# DSS_CTRL register map
Vendor: Texas Instruments
Peripheral module from a debugger description file (folder awr2x44p).
Registers are 32-bit, read-write, no defined reset value unless marked. A register's access mark holds for its fields unless they carry their own. Offsets are as the file gives them; lines under a group give offsets from that group; [hi:lo] are bit positions; {n}, {i} and the like mark numbered series; 'fields as' and 'values as' point back to an identical list; <NAME> marks a mode.

## DSS_CTRL (part 1 of 2)
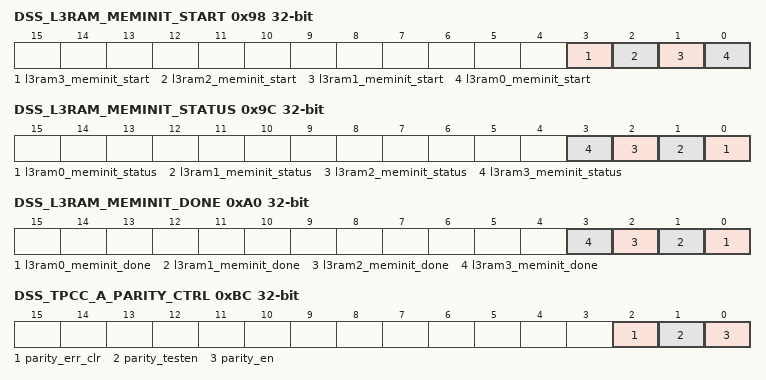
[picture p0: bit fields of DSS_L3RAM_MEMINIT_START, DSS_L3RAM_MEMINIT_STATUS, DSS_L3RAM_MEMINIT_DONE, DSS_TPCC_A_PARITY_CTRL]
0x98 DSS_L3RAM_MEMINIT_START
  [3] l3ram3_meminit_start — Write pulse bit field:Start Memory intialization of TPCC A Param memory. Write 0x1 to start memory initilization. Write 0x0 after ensuring Memory intilization is in progress or has completed. Before starting new initilzation sequence ensure that there is no initilization sequence is in progress (ie L3RAM_MEMINIT_STATUS should be 0x0) and clear any previouls complettion status(ie write 0x1 to clear L3RAM_MEMINIT_DONE)
  [2] l3ram2_meminit_start — Write pulse bit field: Start Memory intialization of TPCC A Param memory. Write 0x1 to start memory initilization. Write 0x0 after ensuring Memory intilization is in progress or has completed. Before starting new initilzation sequence ensure that there is no initilization sequence is in progress (ie L3RAM_MEMINIT_STATUS should be 0x0) and clear any previouls complettion status(ie write 0x1 to clear L3RAM_MEMINIT_DONE)
  [1] l3ram1_meminit_start — Write pulse bit field: Start Memory intialization of TPCC A Param memory. Write 0x1 to start memory initilization. Write 0x0 after ensuring Memory intilization is in progress or has completed. Before starting new initilzation sequence ensure that there is no initilization sequence is in progress (ie L3RAM_MEMINIT_STATUS should be 0x0) and clear any previouls complettion status(ie write 0x1 to clear L3RAM_MEMINIT_DONE)
  [0] l3ram0_meminit_start — Write pulse bit field: Start Memory intialization of TPCC A Param memory. Write 0x1 to start memory initilization. Write 0x0 after ensuring Memory intilization is in progress or has completed. Before starting new initilzation sequence ensure that there is no initilization sequence is in progress (ie L3RAM_MEMINIT_STATUS should be 0x0) and clear any previouls complettion status(ie write 0x1 to clear L3RAM_MEMINIT_DONE)
0x9C DSS_L3RAM_MEMINIT_STATUS ro
  [n] l3ram{n}_meminit_status (n=0..3) — Status field. Read value 0x1 indicates previously triggered Memory intialization of TPCC A Param memory is in progress.
0xA0 DSS_L3RAM_MEMINIT_DONE
  [n] l3ram{n}_meminit_done (n=0..3) — Rising Edge Capture reg (write 1 to clear): Status field. Read value 0x1 indicates previously triggered Memory intialization of TPCC A Param memory is complte. Write 0x1 to clear status. Refer TPCC Memory initialization sequnce in EDMA section for more details
0xB0 DSS_MAILBOX_MEMINIT_START
  [0] meminit_start — Write pulse bit field: Start Memory intialization of TPCC A Param memory. Write 0x1 to start memory initilization. Write 0x0 after ensuring Memory intilization is in progress or has completed. Before starting new initilzation sequence ensure that there is no initilization sequence is in progress (ie L3RAM_MEMINIT_STATUS should be 0x0) and clear any previouls complettion status(ie write 0x1 to clear L3RAM_MEMINIT_DONE)
0xB4 DSS_MAILBOX_MEMINIT_STATUS ro
  [0] meminit_status — Status field. Read value 0x1 indicates previously triggered Memory intialization of TPCC A Param memory is in progress.
0xB8 DSS_MAILBOX_MEMINIT_DONE
  [0] meminit_done — Rising Edge Capture reg (write 1 to clear): Status field. Read value 0x1 indicates previously triggered Memory intialization of TPCC A Param memory is complte. Write 0x1 to clear status. Refer TPCC Memory initialization sequnce in EDMA section for more details
0xBC DSS_TPCC_A_PARITY_CTRL
  [2] parity_err_clr — Write pulse bit field: Write 0x1 to clear the Parit Error status for TPCC
  [1] parity_testen — Enable Parity Test for TPCC. Write 0x1 : Parity Test is enabled on PARAM memory
  [0] parity_en — Enable Parity for TPCC. Write 0x1 : Parity is enabled on PARAM memory
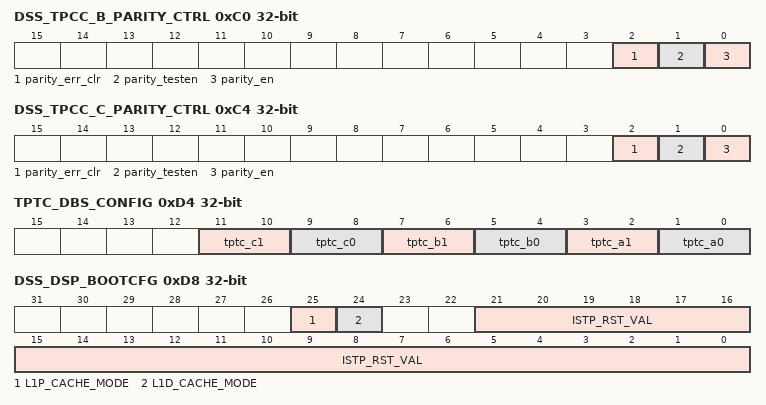
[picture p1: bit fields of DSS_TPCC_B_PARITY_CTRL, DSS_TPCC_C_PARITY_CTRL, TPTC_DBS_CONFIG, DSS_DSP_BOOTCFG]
0xC0 DSS_TPCC_B_PARITY_CTRL
  fields as DSS_TPCC_A_PARITY_CTRL
0xC4 DSS_TPCC_C_PARITY_CTRL
  fields as DSS_TPCC_A_PARITY_CTRL
0xC8 DSS_TPCC_A_PARITY_STATUS ro
  [7:0] parity_addr — TPCC Error Address at which Parity Error occurred
0xCC DSS_TPCC_B_PARITY_STATUS ro
  fields as DSS_TPCC_A_PARITY_STATUS
0xD0 DSS_TPCC_C_PARITY_STATUS ro
  [8:0] parity_addr — TPCC Error Address at which Parity Error occurred
0xD4 TPTC_DBS_CONFIG
  [11:10] tptc_c1 — Max Burst size tieoff value for TPTC C1
  [9:8] tptc_c0 — Max Burst size tieoff value for TPTC C0
  [7:6] tptc_b1 — Max Burst size tieoff value for TPTC B0
  [5:4] tptc_b0 — Max Burst size tieoff value for TPTC B0
  [3:2] tptc_a1 — Max Burst size tieoff value for TPTC A1
  [1:0] tptc_a0 — Max Burst size tieoff value for TPTC A0
0xD8 DSS_DSP_BOOTCFG
  [25] L1P_CACHE_MODE — DSP Boot Configuration : L1P Cache Mode
  [24] L1D_CACHE_MODE — DSP Boot Configuration : L1D Cache Mode
  [21:0] ISTP_RST_VAL — DSP Boot Configuration : Reset Vector
0xDC DSS_DSP_NMI_GATE
  [2:0] gate — Write 3b111 to gate the Non Maskable Interrupt to the DSP. This is not expected to be used
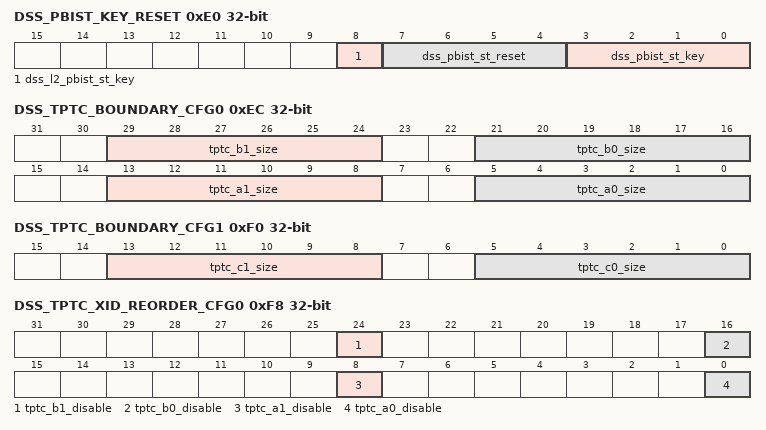
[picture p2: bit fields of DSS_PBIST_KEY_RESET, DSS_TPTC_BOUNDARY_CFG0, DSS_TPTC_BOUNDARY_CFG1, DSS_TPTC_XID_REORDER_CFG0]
0xE0 DSS_PBIST_KEY_RESET
  [8] dss_l2_pbist_st_key — DSS L2 PBIST Selftest Key.
  [7:4] dss_pbist_st_reset — DSS PBIST controller will be brought out of reset when value is 0xA
  [3:0] dss_pbist_st_key — DSS PBIST Selftest Key. Valid value is 0x5
0xE4 DSS_PBIST_REG0
  [31:0] dss_pbist_reg0 — DSP PBIST registers
0xE8 DSS_PBIST_REG1
  [31:0] dss_pbist_reg1 — DSP PBIST registers
0xEC DSS_TPTC_BOUNDARY_CFG0
  [29:24] tptc_b1_size — 6 bit signal used for deciding the boundary crossing size for CID-RID-SID reordering of TPTC Example: writing 6d19 decidies boundary to be 2^19 i.e. 512 KB
  [21:16] tptc_b0_size — 6 bit signal used for deciding the boundary crossing size for CID-RID-SID reordering of TPTC Example: writing 6d19 decidies boundary to be 2^19 i.e. 512 KB
  [13:8] tptc_a1_size — 6 bit signal used for deciding the boundary crossing size for CID-RID-SID reordering of TPTC Example: writing 6d19 decidies boundary to be 2^19 i.e. 512 KB
  [5:0] tptc_a0_size — 6 bit signal used for deciding the boundary crossing size for CID-RID-SID reordering of TPTC Example: writing 6d19 decidies boundary to be 2^19 i.e. 512 KB
0xF0 DSS_TPTC_BOUNDARY_CFG1
  [13:8] tptc_c1_size — 6 bit signal used for deciding the boundary crossing size for CID-RID-SID reordering of TPTC Example: writing 6d19 decidies boundary to be 2^19 i.e. 512 KB
  [5:0] tptc_c0_size — 6 bit signal used for deciding the boundary crossing size for CID-RID-SID reordering of TPTC Example: writing 6d19 decidies boundary to be 2^19 i.e. 512 KB
0xF8 DSS_TPTC_XID_REORDER_CFG0
  [24] tptc_b1_disable — Writing 1b1 will disable the CID-RID-SID reodering feature for the TPTC instance
  [16] tptc_b0_disable — Writing 1b1 will disable the CID-RID-SID reodering feature for the TPTC instance
  [8] tptc_a1_disable — Writing 1b1 will disable the CID-RID-SID reodering feature for the TPTC instance
  [0] tptc_a0_disable — Writing 1b1 will disable the CID-RID-SID reodering feature for the TPTC instance
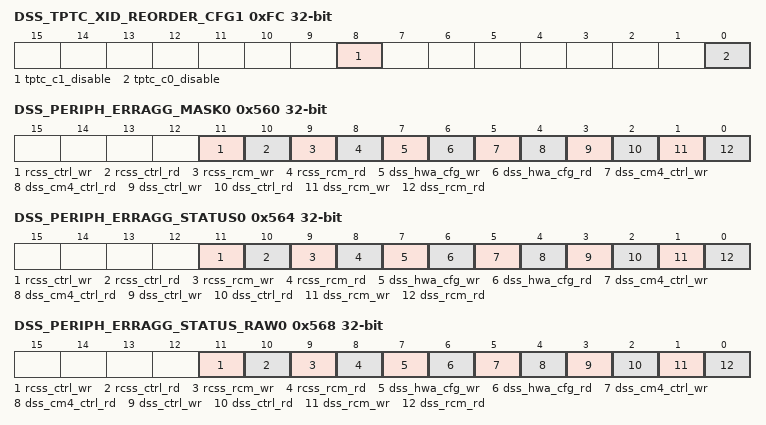
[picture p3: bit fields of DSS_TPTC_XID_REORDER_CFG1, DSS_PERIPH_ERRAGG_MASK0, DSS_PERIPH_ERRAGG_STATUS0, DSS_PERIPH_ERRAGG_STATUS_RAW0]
0xFC DSS_TPTC_XID_REORDER_CFG1
  [8] tptc_c1_disable — Writing 1b1 will disable the CID-RID-SID reodering feature for the TPTC instance
  [0] tptc_c0_disable — Writing 1b1 will disable the CID-RID-SID reodering feature for the TPTC instance
{0x108+4i} ESM_GATING{i} (i=0..3)
  [31:0] esm_gating — Bit3:0 : writing 000 will ungate the DSS ESM Group2 Error {8i} Bit7:4 : writing 000 will ungate the DSS ESM Group2 Error {8i+1} Bit31:28 : writing 000 will ungate the DSS ESM Group2 Error {8i+7}
0x560 DSS_PERIPH_ERRAGG_MASK0
  [11] rcss_ctrl_wr — Mask the Write error from RCSS_CTRL space from generating an error DSS_PERIPH_ERRAGG to the Processor
  [10] rcss_ctrl_rd — Mask the Read error from RCSS_CTRL space from generating an error DSS_PERIPH_ERRAGG to the Processor
  [9] rcss_rcm_wr — Mask the Write error from RCSS_RCM space from generating an error DSS_PERIPH_ERRAGG to the Processor
  [8] rcss_rcm_rd — Mask the Read error from RCSS_RCM space from generating an error DSS_PERIPH_ERRAGG to the Processor
  [7] dss_hwa_cfg_wr — Mask the Write error from DSS_HWA_CFG space from generating an error DSS_PERIPH_ERRAGG to the Processor
  [6] dss_hwa_cfg_rd — Mask the Read error from DSS_HWA_CFG space from generating an error DSS_PERIPH_ERRAGG to the Processor
  [5] dss_cm4_ctrl_wr — Mask the Write error from DSS_CM4_CTRL space from generating an error DSS_PERIPH_ERRAGG to the Processor
  [4] dss_cm4_ctrl_rd — Mask the Read error from DSS_CM4_CTRL space from generating an error DSS_PERIPH_ERRAGG to the Processor
  [3] dss_ctrl_wr — Mask the Write error from DSS_CTRL space from generating an error DSS_PERIPH_ERRAGG to the Processor
  [2] dss_ctrl_rd — Mask the Read error from DSS_CTRL space from generating an error DSS_PERIPH_ERRAGG to the Processor
  [1] dss_rcm_wr — Mask the Write error from DSS_RCM space from generating an error DSS_PERIPH_ERRAGG to the Processor
  [0] dss_rcm_rd — Mask the Read error from DSS_RCM space from generating an error DSS_PERIPH_ERRAGG to the Processor
0x564 DSS_PERIPH_ERRAGG_STATUS0
  [11] rcss_ctrl_wr — Rising Edge Capture reg (write 1 to clear): Status of the Write error from RCSS_CTRL space. Read 1 : Read error occurred on access to the RCSS_CTRL space
  [10] rcss_ctrl_rd — Rising Edge Capture reg (write 1 to clear): Status of the Read error from RCSS_CTRL space. Read 1 : Read error occurred on access to the RCSS_CTRL space
  [9] rcss_rcm_wr — Rising Edge Capture reg (write 1 to clear): Status of the Write error from RCSS_RCM space. Read 1 : Read error occurred on access to the RCSS_RCM space
  [8] rcss_rcm_rd — Rising Edge Capture reg (write 1 to clear): Status of the Read error from RCSS_RCM space. Read 1 : Read error occurred on access to the RCSS_RCM space
  [7] dss_hwa_cfg_wr — Rising Edge Capture reg (write 1 to clear): Status of the Write error from DSS_HWA_CFG space. Read 1 : Read error occurred on access to the DSS_HWA_CFG space
  [6] dss_hwa_cfg_rd — Rising Edge Capture reg (write 1 to clear): Status of the Read error from DSS_HWA_CFG space. Read 1 : Read error occurred on access to the DSS_HWA_CFG space
  [5] dss_cm4_ctrl_wr — Rising Edge Capture reg (write 1 to clear): Status of the Write error from DSS_CM4_CTRL space. Read 1 : Read error occurred on access to the DSS_CM4_CTRL space
  [4] dss_cm4_ctrl_rd — Rising Edge Capture reg (write 1 to clear): Status of the Read error from DSS_CM4_CTRL space. Read 1 : Read error occurred on access to the DSS_CM4_CTRL space
  [3] dss_ctrl_wr — Rising Edge Capture reg (write 1 to clear): Status of the Write error from DSS_CTRL space. Read 1 : Read error occurred on access to the DSS_CTRL space
  [2] dss_ctrl_rd — Rising Edge Capture reg (write 1 to clear): Status of the Read error from DSS_CTRL space. Read 1 : Read error occurred on access to the DSS_CTRL space
  [1] dss_rcm_wr — Rising Edge Capture reg (write 1 to clear): Status of the Write error from DSS_RCM space. Read 1 : Read error occurred on access to the DSS_RCM space
  [0] dss_rcm_rd — Rising Edge Capture reg (write 1 to clear): Rising Edge Capture reg (write 1 to clear): Status of the Read error from DSS_RCM space. Read 1 : Read error occurred on access to the DSS_RCM space
0x568 DSS_PERIPH_ERRAGG_STATUS_RAW0
  [11] rcss_ctrl_wr — Rising Edge Capture reg (write 1 to clear): Raw Status of the Write error from RCSS_CTRL space irrespective of it being masked. Read 1 : Read error occurred on access to the RCSS_CTRL space
  [10] rcss_ctrl_rd — Rising Edge Capture reg (write 1 to clear): Raw Status of the Read error from RCSS_CTRL space irrespective of it being masked. Read 1 : Read error occurred on access to the RCSS_CTRL space
  [9] rcss_rcm_wr — Rising Edge Capture reg (write 1 to clear): Raw Status of the Write error from RCSS_RCM space irrespective of it being masked. Read 1 : Read error occurred on access to the RCSS_RCM space
  [8] rcss_rcm_rd — Rising Edge Capture reg (write 1 to clear): Raw Status of the Read error from RCSS_RCM space irrespective of it being masked. Read 1 : Read error occurred on access to the RCSS_RCM space
  [7] dss_hwa_cfg_wr — Rising Edge Capture reg (write 1 to clear): Raw Status of the Write error from DSS_HWA_CFG space irrespective of it being masked. Read 1 : Read error occurred on access to the DSS_HWA_CFG space
  [6] dss_hwa_cfg_rd — Rising Edge Capture reg (write 1 to clear): Raw Status of the Read error from DSS_HWA_CFG space irrespective of it being masked. Read 1 : Read error occurred on access to the DSS_HWA_CFG space
  [5] dss_cm4_ctrl_wr — Rising Edge Capture reg (write 1 to clear): Raw Status of the Write error from DSS_CM4_CTRL space irrespective of it being masked. Read 1 : Read error occurred on access to the DSS_CM4_CTRL space
  [4] dss_cm4_ctrl_rd — Rising Edge Capture reg (write 1 to clear): Raw Status of the Read error from DSS_CM4_CTRL space irrespective of it being masked. Read 1 : Read error occurred on access to the DSS_CM4_CTRL space
  [3] dss_ctrl_wr — Rising Edge Capture reg (write 1 to clear): Raw Status of the Write error from DSS_CTRL space irrespective of it being masked. Read 1 : Read error occurred on access to the DSS_CTRL space
  [2] dss_ctrl_rd — Rising Edge Capture reg (write 1 to clear): Raw Status of the Read error from DSS_CTRL space irrespective of it being masked. Read 1 : Read error occurred on access to the DSS_CTRL space
  [1] dss_rcm_wr — Rising Edge Capture reg (write 1 to clear): Raw Status of the Write error from DSS_RCM space irrespective of it being masked. Read 1 : Read error occurred on access to the DSS_RCM space
  [0] dss_rcm_rd — Rising Edge Capture reg (write 1 to clear): Raw Status of the Read error from DSS_RCM space irrespective of it being masked. Read 1 : Read error occurred on access to the DSS_RCM space
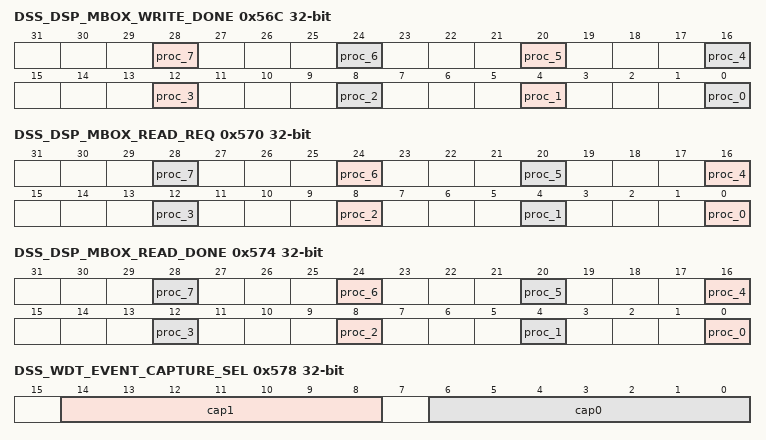
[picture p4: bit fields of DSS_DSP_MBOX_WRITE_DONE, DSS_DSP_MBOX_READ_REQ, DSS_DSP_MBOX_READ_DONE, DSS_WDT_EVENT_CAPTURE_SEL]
0x56C DSS_DSP_MBOX_WRITE_DONE
  [28] proc_7 — Write pulse bit field:This register should be written once finishing writing into the mailbox memory of processor 7
  [4n] proc_{n} (n=0..6) — Write pulse bit field: This register should be written once finishing writing into the mailbox memory of processor {n}
0x570 DSS_DSP_MBOX_READ_REQ
  [4n] proc_{n} (n=0..7) — Rising Edge Capture reg (write 1 to clear): This is request from processor {n} to DSS_DSP. Requesting it to read from mailbox.
0x574 DSS_DSP_MBOX_READ_DONE
  [4n] proc_{n} (n=0..7) — Rising Edge Capture reg (write 1 to clear): This register should be written once finishing reading from DSS_DSPs mailbox written by proc {n}
0x578 DSS_WDT_EVENT_CAPTURE_SEL
  [14:8] cap1 — Select the DSS_WDT Capture Event 1 from the DSS DSP Interrupt Map
  [6:0] cap0 — Select the DSS_WDT Capture Event 0 from the DSS DSP Interrupt Map
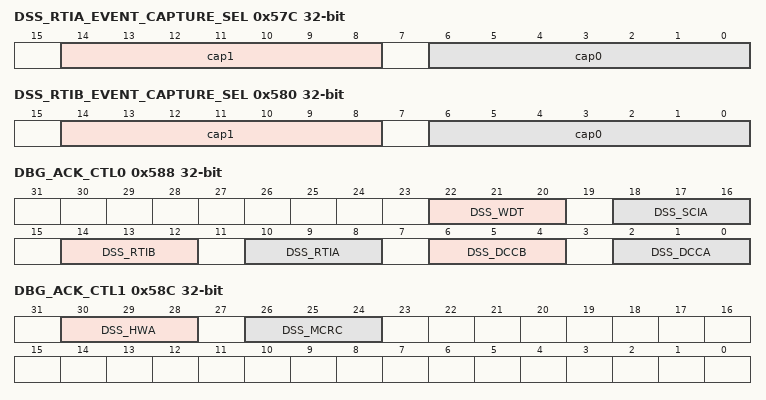
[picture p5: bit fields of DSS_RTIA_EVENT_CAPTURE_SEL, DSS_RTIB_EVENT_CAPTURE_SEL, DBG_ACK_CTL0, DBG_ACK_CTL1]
0x57C DSS_RTIA_EVENT_CAPTURE_SEL
  [14:8] cap1 — Select the DSS_RTIA Capture Event 1 from the DSS DSP Interrupt Map
  [6:0] cap0 — Select the DSS_RTIA Capture Event 0 from the DSS DSP Interrupt Map
0x580 DSS_RTIB_EVENT_CAPTURE_SEL
  [14:8] cap1 — Select the DSS_RTIB Capture Event 1 from the DSS DSP Interrupt Map
  [6:0] cap0 — Select the DSS_RTIB Capture Event 0 from the DSS DSP Interrupt Map
0x584 DBG_ACK_CPU_CTRL
  [0] sel — Select the Processor Suspend that is used to Suspend the DSS Peripehrals 0: DSP 1:MSS CR5
0x588 DBG_ACK_CTL0
  [22:20] DSS_WDT — Enable Suspend control for the peripheral. 0 :Peripheral not suspended along with processor 1: Peripehal Suspended along with procesor
  [18:16] DSS_SCIA — Enable Suspend control for the peripheral. 0 :Peripheral not suspended along with processor 1: Peripehal Suspended along with procesor
  [14:12] DSS_RTIB — Enable Suspend control for the peripheral. 0 :Peripheral not suspended along with processor 1: Peripehal Suspended along with procesor
  [10:8] DSS_RTIA — Enable Suspend control for the peripheral. 0 :Peripheral not suspended along with processor 1: Peripehal Suspended along with procesor
  [6:4] DSS_DCCB — Enable Suspend control for the peripheral. 0 :Peripheral not suspended along with processor 1: Peripehal Suspended along with procesor
  [2:0] DSS_DCCA — Enable Suspend control for the peripheral. 0 :Peripheral not suspended along with processor 1: Peripehal Suspended along with procesor
0x58C DBG_ACK_CTL1
  [30:28] DSS_HWA — Enable Suspend control for the peripheral. 0 :Peripheral not suspended along with processor 1: Peripehal Suspended along with procesor
  [26:24] DSS_MCRC — Enable Suspend control for the peripheral. 0 :Peripheral not suspended along with processor 1: Peripehal Suspended along with procesor
0x590 DSS_DSP_INT_SEL
  [2:0] RCSS_CSI2_ICSSM — DSS DSP Interrupt selcet 0x0: CSI2 Interrupts are propagated to DSP 0x7 : ICSSM Interrupts are propagted to DSP
0x594 DSS_CBUFF_TRIGGER_SEL
  [6:0] sel — DSS CBUFF HW Trigger select from DSS DSP Interrupt Map. Reset value selects RSS_ADC_CAPTURE_COMPLETE as cbuff trigger
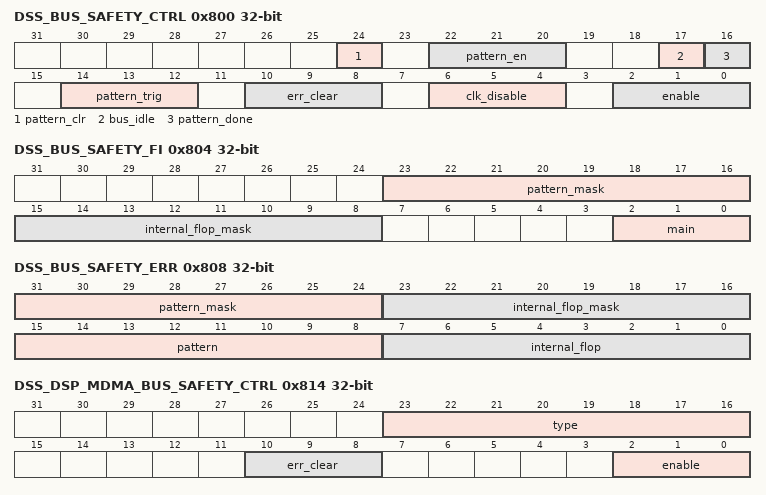
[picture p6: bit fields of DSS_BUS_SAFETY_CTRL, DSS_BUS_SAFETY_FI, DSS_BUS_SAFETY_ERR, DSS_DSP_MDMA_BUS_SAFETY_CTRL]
0x800 DSS_BUS_SAFETY_CTRL access per field
  [24] pattern_clr rw — Refer bus safety confluence page https://confluence.itg.ti.com/pages/viewpage.action?spaceKey=RadarPlatforms&title=Bus+Safety+-+AWR2944P
  [22:20] pattern_en rw — Refer bus safety confluence page https://confluence.itg.ti.com/pages/viewpage.action?spaceKey=RadarPlatforms&title=Bus+Safety+-+AWR2944P
  [17] bus_idle ro — Refer bus safety confluence page https://confluence.itg.ti.com/pages/viewpage.action?spaceKey=RadarPlatforms&title=Bus+Safety+-+AWR2944P
  [16] pattern_done ro — Refer bus safety confluence page https://confluence.itg.ti.com/pages/viewpage.action?spaceKey=RadarPlatforms&title=Bus+Safety+-+AWR2944P
  [14:12] pattern_trig rw — Write pulse bit field:Refer bus safety confluence page https://confluence.itg.ti.com/pages/viewpage.action?spaceKey=RadarPlatforms&title=Bus+Safety+-+AWR2944P
  [10:8] err_clear rw — Refer bus safety confluence page https://confluence.itg.ti.com/pages/viewpage.action?spaceKey=RadarPlatforms&title=Bus+Safety+-+AWR2944P
  [6:4] clk_disable rw — Refer bus safety confluence page https://confluence.itg.ti.com/pages/viewpage.action?spaceKey=RadarPlatforms&title=Bus+Safety+-+AWR2944P
  [2:0] enable rw — Refer bus safety confluence page https://confluence.itg.ti.com/pages/viewpage.action?spaceKey=RadarPlatforms&title=Bus+Safety+-+AWR2944P
0x804 DSS_BUS_SAFETY_FI
  [23:16] pattern_mask — Refer bus safety confluence page https://confluence.itg.ti.com/pages/viewpage.action?spaceKey=RadarPlatforms&title=Bus+Safety+-+AWR2944P
  [15:8] internal_flop_mask — Refer bus safety confluence page https://confluence.itg.ti.com/pages/viewpage.action?spaceKey=RadarPlatforms&title=Bus+Safety+-+AWR2944P
  [2:0] main — Refer bus safety confluence page https://confluence.itg.ti.com/pages/viewpage.action?spaceKey=RadarPlatforms&title=Bus+Safety+-+AWR2944P
0x808 DSS_BUS_SAFETY_ERR access per field
  [31:24] pattern_mask rw — Refer bus safety confluence page https://confluence.itg.ti.com/pages/viewpage.action?spaceKey=RadarPlatforms&title=Bus+Safety+-+AWR2944P
  [23:16] internal_flop_mask rw — Refer bus safety confluence page https://confluence.itg.ti.com/pages/viewpage.action?spaceKey=RadarPlatforms&title=Bus+Safety+-+AWR2944P
  [15:8] pattern ro — Refer bus safety confluence page https://confluence.itg.ti.com/pages/viewpage.action?spaceKey=RadarPlatforms&title=Bus+Safety+-+AWR2944P
  [7:0] internal_flop ro — Refer bus safety confluence page https://confluence.itg.ti.com/pages/viewpage.action?spaceKey=RadarPlatforms&title=Bus+Safety+-+AWR2944P
0x814 DSS_DSP_MDMA_BUS_SAFETY_CTRL access per field
  [23:16] type ro — undefined : command channel undefined : write channel undefined : write status channel undefined : read channel
  [10:8] err_clear rw — Write pulse bit field:Refer bus safety confluence page https://confluence.itg.ti.com/pages/viewpage.action?spaceKey=RadarPlatforms&title=Bus+Safety+-+AWR2944P
  [2:0] enable rw — Refer bus safety confluence page https://confluence.itg.ti.com/pages/viewpage.action?spaceKey=RadarPlatforms&title=Bus+Safety+-+AWR2944P
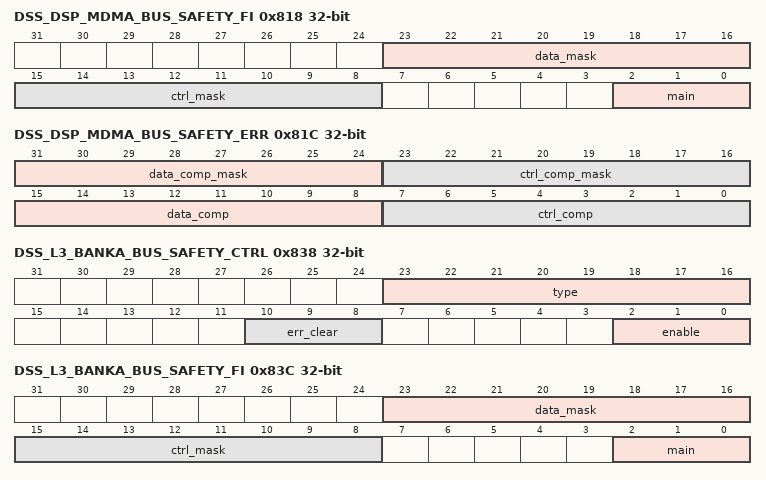
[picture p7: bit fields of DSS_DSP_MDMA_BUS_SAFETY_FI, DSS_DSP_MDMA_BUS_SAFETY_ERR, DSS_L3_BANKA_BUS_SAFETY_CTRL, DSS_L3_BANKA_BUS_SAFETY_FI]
0x818 DSS_DSP_MDMA_BUS_SAFETY_FI
  [23:16] data_mask — Refer bus safety confluence page https://confluence.itg.ti.com/pages/viewpage.action?spaceKey=RadarPlatforms&title=Bus+Safety+-+AWR2944P
  [15:8] ctrl_mask — Refer bus safety confluence page https://confluence.itg.ti.com/pages/viewpage.action?spaceKey=RadarPlatforms&title=Bus+Safety+-+AWR2944P
  [2:0] main — Refer bus safety confluence page https://confluence.itg.ti.com/pages/viewpage.action?spaceKey=RadarPlatforms&title=Bus+Safety+-+AWR2944P
0x81C DSS_DSP_MDMA_BUS_SAFETY_ERR access per field
  [31:24] data_comp_mask rw — Refer bus safety confluence page https://confluence.itg.ti.com/pages/viewpage.action?spaceKey=RadarPlatforms&title=Bus+Safety+-+AWR2944P
  [23:16] ctrl_comp_mask rw — Refer bus safety confluence page https://confluence.itg.ti.com/pages/viewpage.action?spaceKey=RadarPlatforms&title=Bus+Safety+-+AWR2944P
  [15:8] data_comp ro — Refer bus safety confluence page https://confluence.itg.ti.com/pages/viewpage.action?spaceKey=RadarPlatforms&title=Bus+Safety+-+AWR2944P
  [7:0] ctrl_comp ro — Refer bus safety confluence page https://confluence.itg.ti.com/pages/viewpage.action?spaceKey=RadarPlatforms&title=Bus+Safety+-+AWR2944P
0x838 DSS_L3_BANKA_BUS_SAFETY_CTRL access per field
  fields as DSS_DSP_MDMA_BUS_SAFETY_CTRL
0x83C DSS_L3_BANKA_BUS_SAFETY_FI
  fields as DSS_DSP_MDMA_BUS_SAFETY_FI
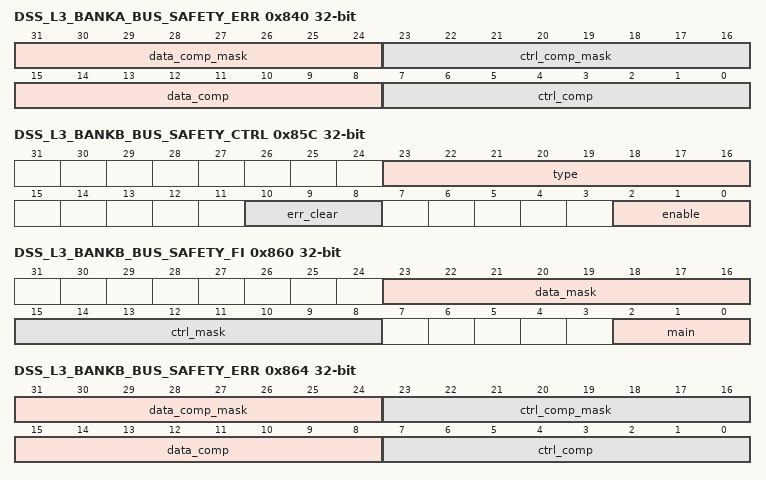
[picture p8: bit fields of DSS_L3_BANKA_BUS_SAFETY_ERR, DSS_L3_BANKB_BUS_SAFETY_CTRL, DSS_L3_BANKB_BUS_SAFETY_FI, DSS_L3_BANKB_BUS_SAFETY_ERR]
0x840 DSS_L3_BANKA_BUS_SAFETY_ERR access per field
  fields as DSS_DSP_MDMA_BUS_SAFETY_ERR
0x85C DSS_L3_BANKB_BUS_SAFETY_CTRL access per field
  fields as DSS_DSP_MDMA_BUS_SAFETY_CTRL
0x860 DSS_L3_BANKB_BUS_SAFETY_FI
  fields as DSS_DSP_MDMA_BUS_SAFETY_FI
0x864 DSS_L3_BANKB_BUS_SAFETY_ERR access per field
  fields as DSS_DSP_MDMA_BUS_SAFETY_ERR
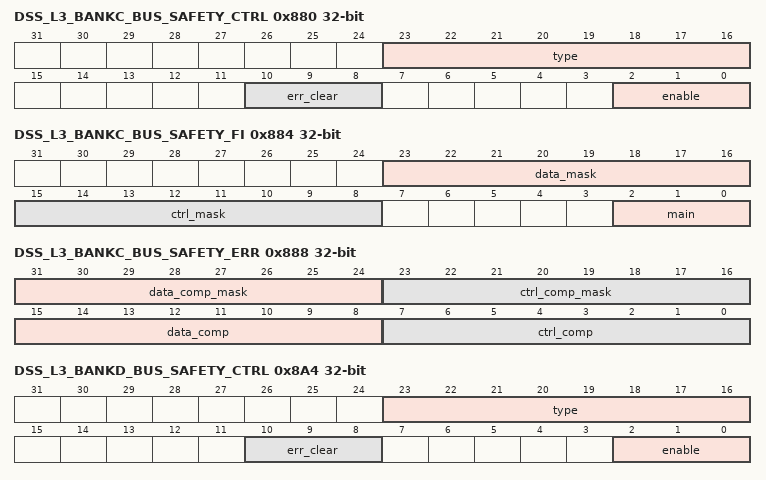
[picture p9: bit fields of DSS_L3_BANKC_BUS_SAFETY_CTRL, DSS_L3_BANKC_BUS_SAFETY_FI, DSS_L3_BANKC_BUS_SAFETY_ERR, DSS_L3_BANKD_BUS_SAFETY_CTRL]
0x880 DSS_L3_BANKC_BUS_SAFETY_CTRL access per field
  fields as DSS_DSP_MDMA_BUS_SAFETY_CTRL
0x884 DSS_L3_BANKC_BUS_SAFETY_FI
  fields as DSS_DSP_MDMA_BUS_SAFETY_FI
0x888 DSS_L3_BANKC_BUS_SAFETY_ERR access per field
  fields as DSS_DSP_MDMA_BUS_SAFETY_ERR
0x8A4 DSS_L3_BANKD_BUS_SAFETY_CTRL access per field
  fields as DSS_DSP_MDMA_BUS_SAFETY_CTRL
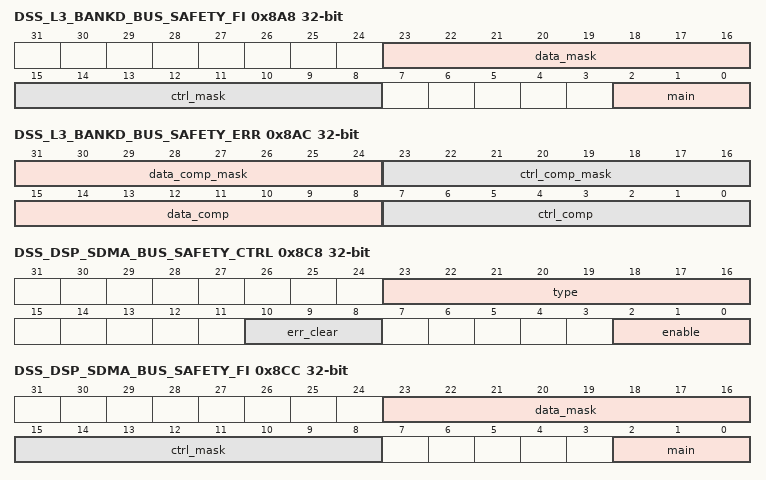
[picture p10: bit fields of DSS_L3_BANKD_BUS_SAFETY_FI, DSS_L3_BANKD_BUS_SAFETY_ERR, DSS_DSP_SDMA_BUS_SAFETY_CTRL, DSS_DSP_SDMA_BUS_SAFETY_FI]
0x8A8 DSS_L3_BANKD_BUS_SAFETY_FI
  fields as DSS_DSP_MDMA_BUS_SAFETY_FI
0x8AC DSS_L3_BANKD_BUS_SAFETY_ERR access per field
  fields as DSS_DSP_MDMA_BUS_SAFETY_ERR
0x8C8 DSS_DSP_SDMA_BUS_SAFETY_CTRL access per field
  fields as DSS_DSP_MDMA_BUS_SAFETY_CTRL
0x8CC DSS_DSP_SDMA_BUS_SAFETY_FI
  fields as DSS_DSP_MDMA_BUS_SAFETY_FI
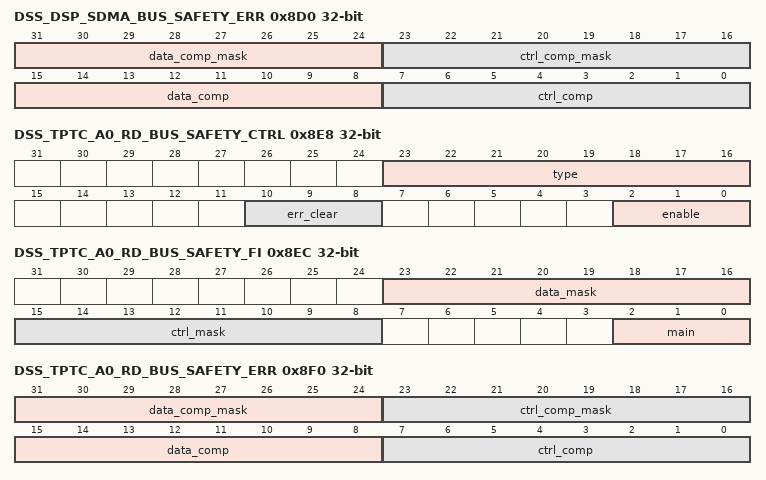
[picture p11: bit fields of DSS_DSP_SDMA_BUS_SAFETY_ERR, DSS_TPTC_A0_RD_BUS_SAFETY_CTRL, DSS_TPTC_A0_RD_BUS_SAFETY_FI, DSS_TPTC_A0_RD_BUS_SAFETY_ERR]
0x8D0 DSS_DSP_SDMA_BUS_SAFETY_ERR access per field
  fields as DSS_DSP_MDMA_BUS_SAFETY_ERR
0x8E8 DSS_TPTC_A0_RD_BUS_SAFETY_CTRL access per field
  fields as DSS_DSP_MDMA_BUS_SAFETY_CTRL
0x8EC DSS_TPTC_A0_RD_BUS_SAFETY_FI
  fields as DSS_DSP_MDMA_BUS_SAFETY_FI
0x8F0 DSS_TPTC_A0_RD_BUS_SAFETY_ERR access per field
  fields as DSS_DSP_MDMA_BUS_SAFETY_ERR
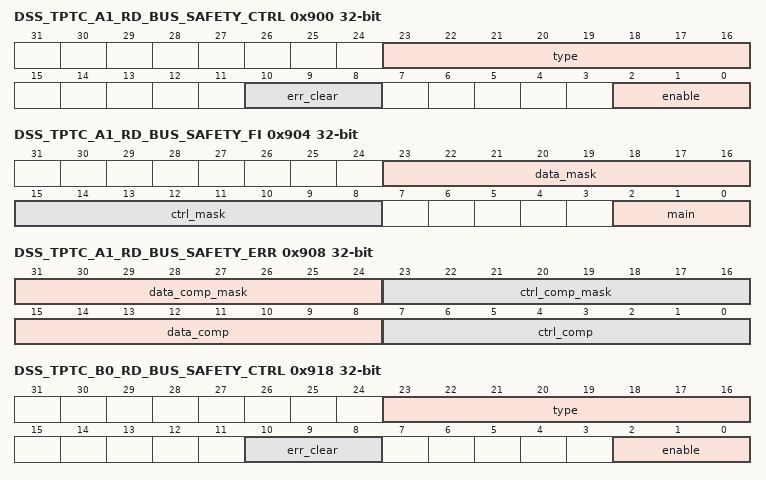
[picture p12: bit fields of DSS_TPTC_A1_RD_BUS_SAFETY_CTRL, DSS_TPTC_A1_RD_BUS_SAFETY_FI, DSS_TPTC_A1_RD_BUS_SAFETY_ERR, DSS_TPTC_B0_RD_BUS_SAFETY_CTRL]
0x900 DSS_TPTC_A1_RD_BUS_SAFETY_CTRL access per field
  fields as DSS_DSP_MDMA_BUS_SAFETY_CTRL
0x904 DSS_TPTC_A1_RD_BUS_SAFETY_FI
  fields as DSS_DSP_MDMA_BUS_SAFETY_FI
0x908 DSS_TPTC_A1_RD_BUS_SAFETY_ERR access per field
  fields as DSS_DSP_MDMA_BUS_SAFETY_ERR
0x918 DSS_TPTC_B0_RD_BUS_SAFETY_CTRL access per field
  fields as DSS_DSP_MDMA_BUS_SAFETY_CTRL
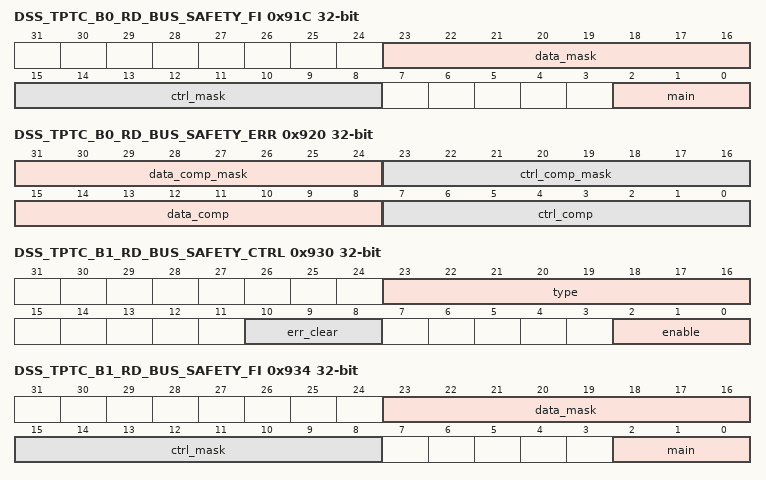
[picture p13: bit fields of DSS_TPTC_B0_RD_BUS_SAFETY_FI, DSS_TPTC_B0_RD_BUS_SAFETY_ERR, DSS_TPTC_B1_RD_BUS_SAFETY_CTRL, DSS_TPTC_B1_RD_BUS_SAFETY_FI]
0x91C DSS_TPTC_B0_RD_BUS_SAFETY_FI
  fields as DSS_DSP_MDMA_BUS_SAFETY_FI
0x920 DSS_TPTC_B0_RD_BUS_SAFETY_ERR access per field
  fields as DSS_DSP_MDMA_BUS_SAFETY_ERR
0x930 DSS_TPTC_B1_RD_BUS_SAFETY_CTRL access per field
  fields as DSS_DSP_MDMA_BUS_SAFETY_CTRL
0x934 DSS_TPTC_B1_RD_BUS_SAFETY_FI
  fields as DSS_DSP_MDMA_BUS_SAFETY_FI
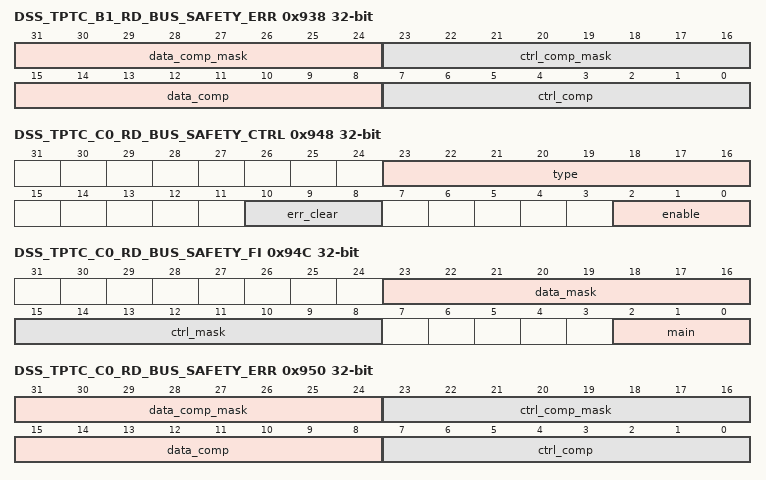
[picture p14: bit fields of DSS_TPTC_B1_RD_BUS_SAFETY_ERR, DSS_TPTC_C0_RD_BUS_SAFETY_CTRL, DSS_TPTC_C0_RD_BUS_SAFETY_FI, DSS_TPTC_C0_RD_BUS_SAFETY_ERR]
0x938 DSS_TPTC_B1_RD_BUS_SAFETY_ERR access per field
  fields as DSS_DSP_MDMA_BUS_SAFETY_ERR
0x948 DSS_TPTC_C0_RD_BUS_SAFETY_CTRL access per field
  fields as DSS_DSP_MDMA_BUS_SAFETY_CTRL
0x94C DSS_TPTC_C0_RD_BUS_SAFETY_FI
  fields as DSS_DSP_MDMA_BUS_SAFETY_FI
0x950 DSS_TPTC_C0_RD_BUS_SAFETY_ERR access per field
  fields as DSS_DSP_MDMA_BUS_SAFETY_ERR
0x960 DSS_TPTC_C1_RD_BUS_SAFETY_CTRL access per field
  fields as DSS_DSP_MDMA_BUS_SAFETY_CTRL
0x964 DSS_TPTC_C1_RD_BUS_SAFETY_FI
  fields as DSS_DSP_MDMA_BUS_SAFETY_FI
0x968 DSS_TPTC_C1_RD_BUS_SAFETY_ERR access per field
  fields as DSS_DSP_MDMA_BUS_SAFETY_ERR
0x9D8 DSS_TPTC_A0_WR_BUS_SAFETY_CTRL access per field
  fields as DSS_DSP_MDMA_BUS_SAFETY_CTRL
0x9DC DSS_TPTC_A0_WR_BUS_SAFETY_FI
  fields as DSS_DSP_MDMA_BUS_SAFETY_FI
0x9E0 DSS_TPTC_A0_WR_BUS_SAFETY_ERR access per field
  fields as DSS_DSP_MDMA_BUS_SAFETY_ERR
0x9F4 DSS_TPTC_A1_WR_BUS_SAFETY_CTRL access per field
  fields as DSS_DSP_MDMA_BUS_SAFETY_CTRL
0x9F8 DSS_TPTC_A1_WR_BUS_SAFETY_FI
  fields as DSS_DSP_MDMA_BUS_SAFETY_FI
0x9FC DSS_TPTC_A1_WR_BUS_SAFETY_ERR access per field
  fields as DSS_DSP_MDMA_BUS_SAFETY_ERR
0xA10 DSS_TPTC_B0_WR_BUS_SAFETY_CTRL access per field
  fields as DSS_DSP_MDMA_BUS_SAFETY_CTRL
0xA14 DSS_TPTC_B0_WR_BUS_SAFETY_FI
  fields as DSS_DSP_MDMA_BUS_SAFETY_FI
0xA18 DSS_TPTC_B0_WR_BUS_SAFETY_ERR access per field
  fields as DSS_DSP_MDMA_BUS_SAFETY_ERR
0xA2C DSS_TPTC_B1_WR_BUS_SAFETY_CTRL access per field
  fields as DSS_DSP_MDMA_BUS_SAFETY_CTRL
0xA30 DSS_TPTC_B1_WR_BUS_SAFETY_FI
  fields as DSS_DSP_MDMA_BUS_SAFETY_FI
0xA34 DSS_TPTC_B1_WR_BUS_SAFETY_ERR access per field
  fields as DSS_DSP_MDMA_BUS_SAFETY_ERR
0xA48 DSS_TPTC_C0_WR_BUS_SAFETY_CTRL access per field
  fields as DSS_DSP_MDMA_BUS_SAFETY_CTRL
0xA4C DSS_TPTC_C0_WR_BUS_SAFETY_FI
  fields as DSS_DSP_MDMA_BUS_SAFETY_FI
0xA50 DSS_TPTC_C0_WR_BUS_SAFETY_ERR access per field
  fields as DSS_DSP_MDMA_BUS_SAFETY_ERR
0xA64 DSS_TPTC_C1_WR_BUS_SAFETY_CTRL access per field
  fields as DSS_DSP_MDMA_BUS_SAFETY_CTRL
0xA68 DSS_TPTC_C1_WR_BUS_SAFETY_FI
  fields as DSS_DSP_MDMA_BUS_SAFETY_FI
0xA6C DSS_TPTC_C1_WR_BUS_SAFETY_ERR access per field
  fields as DSS_DSP_MDMA_BUS_SAFETY_ERR
0xAF0 DSS_MDO_FIFO_BUS_SAFETY_CTRL access per field
  fields as DSS_DSP_MDMA_BUS_SAFETY_CTRL
0xAF4 DSS_MDO_FIFO_BUS_SAFETY_FI
  fields as DSS_DSP_MDMA_BUS_SAFETY_FI
0xAF8 DSS_MDO_FIFO_BUS_SAFETY_ERR access per field
  fields as DSS_DSP_MDMA_BUS_SAFETY_ERR
0xB10 DSS_CBUFF_FIFO_BUS_SAFETY_CTRL access per field
  fields as DSS_DSP_MDMA_BUS_SAFETY_CTRL
0xB14 DSS_CBUFF_FIFO_BUS_SAFETY_FI
  fields as DSS_DSP_MDMA_BUS_SAFETY_FI
0xB18 DSS_CBUFF_FIFO_BUS_SAFETY_ERR access per field
  fields as DSS_DSP_MDMA_BUS_SAFETY_ERR
0xBD0 DSS_MCRC_BUS_SAFETY_CTRL access per field
  fields as DSS_DSP_MDMA_BUS_SAFETY_CTRL
0xBD4 DSS_MCRC_BUS_SAFETY_FI
  fields as DSS_DSP_MDMA_BUS_SAFETY_FI
0xBD8 DSS_MCRC_BUS_SAFETY_ERR access per field
  fields as DSS_DSP_MDMA_BUS_SAFETY_ERR
0xBF0 DSS_PCR_BUS_SAFETY_CTRL access per field
  fields as DSS_DSP_MDMA_BUS_SAFETY_CTRL
0xBF4 DSS_PCR_BUS_SAFETY_FI
  fields as DSS_DSP_MDMA_BUS_SAFETY_FI
0xBF8 DSS_PCR_BUS_SAFETY_ERR access per field
  fields as DSS_DSP_MDMA_BUS_SAFETY_ERR
0xC10 DSS_HWA_DMA0_BUS_SAFETY_CTRL access per field
  fields as DSS_DSP_MDMA_BUS_SAFETY_CTRL
0xC14 DSS_HWA_DMA0_BUS_SAFETY_FI
  fields as DSS_DSP_MDMA_BUS_SAFETY_FI
0xC18 DSS_HWA_DMA0_BUS_SAFETY_ERR access per field
  fields as DSS_DSP_MDMA_BUS_SAFETY_ERR
0xC30 DSS_HWA_DMA1_BUS_SAFETY_CTRL access per field
  fields as DSS_DSP_MDMA_BUS_SAFETY_CTRL
0xC34 DSS_HWA_DMA1_BUS_SAFETY_FI
  fields as DSS_DSP_MDMA_BUS_SAFETY_FI
0xC38 DSS_HWA_DMA1_BUS_SAFETY_ERR access per field
  fields as DSS_DSP_MDMA_BUS_SAFETY_ERR
0xC50 DSS_CM4_M_BUS_SAFETY_CTRL access per field
  fields as DSS_DSP_MDMA_BUS_SAFETY_CTRL
0xC54 DSS_CM4_M_BUS_SAFETY_FI
  fields as DSS_DSP_MDMA_BUS_SAFETY_FI
0xC58 DSS_CM4_M_BUS_SAFETY_ERR access per field
  fields as DSS_DSP_MDMA_BUS_SAFETY_ERR
0xC70 DSS_CM4_S_BUS_SAFETY_CTRL access per field
  fields as DSS_DSP_MDMA_BUS_SAFETY_CTRL
0xC74 DSS_CM4_S_BUS_SAFETY_FI
  fields as DSS_DSP_MDMA_BUS_SAFETY_FI
0xC78 DSS_CM4_S_BUS_SAFETY_ERR access per field
  fields as DSS_DSP_MDMA_BUS_SAFETY_ERR
0xC90 DSS_MBOX_BUS_SAFETY_CTRL access per field
  fields as DSS_DSP_MDMA_BUS_SAFETY_CTRL
0xC94 DSS_MBOX_BUS_SAFETY_FI
  fields as DSS_DSP_MDMA_BUS_SAFETY_FI
0xC98 DSS_MBOX_BUS_SAFETY_ERR access per field
  fields as DSS_DSP_MDMA_BUS_SAFETY_ERR
0xCB0 DSS_DSS2RSS_BUS_SAFETY_CTRL access per field
  fields as DSS_DSP_MDMA_BUS_SAFETY_CTRL
0xCB4 DSS_DSS2RSS_BUS_SAFETY_FI
  fields as DSS_DSP_MDMA_BUS_SAFETY_FI
0xCB8 DSS_DSS2RSS_BUS_SAFETY_ERR access per field
  fields as DSS_DSP_MDMA_BUS_SAFETY_ERR
0xCD0 DSS_RSS2DSS_BUS_SAFETY_CTRL access per field
  fields as DSS_DSP_MDMA_BUS_SAFETY_CTRL
0xCD4 DSS_RSS2DSS_BUS_SAFETY_FI
  fields as DSS_DSP_MDMA_BUS_SAFETY_FI
0xCD8 DSS_RSS2DSS_BUS_SAFETY_ERR access per field
  fields as DSS_DSP_MDMA_BUS_SAFETY_ERR
0xCF0 DSS_DSS2MSS_BUS_SAFETY_CTRL access per field
  fields as DSS_DSP_MDMA_BUS_SAFETY_CTRL
0xCF4 DSS_DSS2MSS_BUS_SAFETY_FI
  fields as DSS_DSP_MDMA_BUS_SAFETY_FI
0xCF8 DSS_DSS2MSS_BUS_SAFETY_ERR access per field
  fields as DSS_DSP_MDMA_BUS_SAFETY_ERR
0xCFC DSS_MSS2DSS_BUS_SAFETY_CTRL access per field
  fields as DSS_DSP_MDMA_BUS_SAFETY_CTRL
0xD00 DSS_MSS2DSS_BUS_SAFETY_FI
  fields as DSS_DSP_MDMA_BUS_SAFETY_FI
0xD04 DSS_MSS2DSS_BUS_SAFETY_ERR access per field
  fields as DSS_DSP_MDMA_BUS_SAFETY_ERR
0xD08 DSS_BUS_SAFETY_LOOPBACK_SLV_SEL
  [31:0] select — Refer bus safety confluence page https://confluence.itg.ti.com/pages/viewpage.action?spaceKey=RadarPlatforms&title=Bus+Safety+-+AWR2944P
0xD0C DSS_BUS_SAFETY_LOOPBACK_MST_SEL
  fields as DSS_BUS_SAFETY_LOOPBACK_SLV_SEL
0xD1C DSS_DMA_REQ_SEL
  [31:0] select — for dma muxing select
0xD20 DSS_BUS_SAFETY_DEBUG access per field
  [n+16] fsm_status_rec{n} rw (n=0..7) — Refer bus safety confluence page https://confluence.itg.ti.com/pages/viewpage.action?spaceKey=RadarPlatforms&title=Bus+Safety+-+AWR2944P
  [15:8] fsm_status ro — Refer bus safety confluence page https://confluence.itg.ti.com/pages/viewpage.action?spaceKey=RadarPlatforms&title=Bus+Safety+-+AWR2944P
  [6:4] mmr_rst_sel rw — Refer bus safety confluence page https://confluence.itg.ti.com/pages/viewpage.action?spaceKey=RadarPlatforms&title=Bus+Safety+-+AWR2944P
  [2:0] mmr_rst rw — Refer bus safety confluence page https://confluence.itg.ti.com/pages/viewpage.action?spaceKey=RadarPlatforms&title=Bus+Safety+-+AWR2944P
0xD24 DSS_M2M_DSS2MSS_BUS_SAFETY_DEBUG
  [n+8] fsm_status_rec{n} (n=0..7) — Refer bus safety confluence page https://confluence.itg.ti.com/pages/viewpage.action?spaceKey=RadarPlatforms&title=Bus+Safety+-+AWR2944P
  [6:4] mmr_rst_sel — Refer bus safety confluence page https://confluence.itg.ti.com/pages/viewpage.action?spaceKey=RadarPlatforms&title=Bus+Safety+-+AWR2944P
  [2:0] mmr_rst — Refer bus safety confluence page https://confluence.itg.ti.com/pages/viewpage.action?spaceKey=RadarPlatforms&title=Bus+Safety+-+AWR2944P
{0xD28+4i} DSS_M2M_L3RAM{i}_BUS_SAFETY_DEBUG (i=0..3)
  fields as DSS_M2M_DSS2MSS_BUS_SAFETY_DEBUG
{0xD38+4i} DSS_M2SRAM_L3RAM{i}_BUS_SAFETY_DEBUG (i=0..3)
  fields as DSS_M2M_DSS2MSS_BUS_SAFETY_DEBUG
{0xFD0+4i} HW_SPARE_RW{i} (i=0..3)
  [31:0] hw_spare_rw{i} — Reserved for HW R&D
{0xFE0+4i} HW_SPARE_RO{i} ro (i=0..3)
  [31:0] hw_spare_ro{i} — Reserved for HW R&D
0xFF0 HW_SPARE_WPH
  [31:0] proc — Write pulse bit field: For bits 0 to 7: Wrting 1b1 : Generates pulse interrupt to corresponding proc from DSP.
0xFF4 HW_SPARE_REC
  [n] hw_spare_rec{n} (n=0..31) — Rising Edge Capture reg (write 1 to clear): Reserved for HW R&D
0x1008 LOCK0_KICK0 — - KICK0 component
  [31:0] ?
0x100C LOCK0_KICK1 — - KICK1 component
  [31:0] ?
0x1010 intr_raw_status — Interrupt Raw Status/Set Register
  [3] ? — Proxy0 access violation error. Raw status is read. Write a 1 to set the status. Writing a 0 has no effect.
  [2] ? — Kick access violation error. Raw status is read. Write a 1 to set the status. Writing a 0 has no effect.
  [1] ? — Addressing violation error. Raw status is read. Write a 1 to set the status. Writing a 0 has no effect.
  [0] ? — Protection violation error. Raw status is read. Write a 1 to set the status. Writing a 0 has no effect.
0x1014 intr_enabled_status_clear — Interrupt Enabled Status/Clear register
  [3] ? — Proxy0 access violation error. Enabled status is read. Write a 1 to clear the status. Writing a 0 has no effect.
  [2] ? — Kick access violation error. Enabled status is read. Write a 1 to clear the status. Writing a 0 has no effect.
  [1] ? — Addressing violation error. Enabled status is read. Write a 1 to clear the status. Writing a 0 has no effect.
  [0] ? — Protection violation error. Enabled status is read. Write a 1 to clear the status. Writing a 0 has no effect.
0x1018 intr_enable — Interrupt Enable register
  [3] ? — Proxy0 access violation error enable. Write a 1 to set the enable. Writing a 0 has no effect.
  [2] ? — Kick access violation error enable. Write a 1 to set the enable. Writing a 0 has no effect.
  [1] ? — Addressing violation error enable. Write a 1 to set the enable. Writing a 0 has no effect.
  [0] ? — Protection violation error enable. Write a 1 to set the enable. Writing a 0 has no effect.
0x101C intr_enable_clear — Interrupt Enable Clear register
  [3] ? — Proxy0 access violation error enable clear. Write a 1 to clear the enable. Writing a 0 has no effect.
  [2] ? — Kick access violation error enable clear. Write a 1 to clear the enable. Writing a 0 has no effect.
  [1] ? — Addressing violation error enable clear. Write a 1 to clear the enable. Writing a 0 has no effect.
  [0] ? — Protection violation error enable clear. Write a 1 to clear the enable. Writing a 0 has no effect.
0x1020 eoi
  [7:0] ? — EOI vector value. Write this with interrupt distribution value in the chip.
0x1024 fault_address ro
  [31:0] ? — Fault Address.
0x1028 fault_type_status ro
  [6] ? — Non-secure access.
  [5:0] ? — Fault Type 10_0000 = Supervisor read fault - priv = 1 dir = 1 dtype != 1 01_0000 = Supervisor write fault - priv = 1 dir = 0 00_1000 = Supervisor execute fault - priv = 1 dir = 1 dtype = 1 00_0100 = User read fault - priv = 0 dir = 1 dtype = 1 00_0010 = User write fault - priv = 0 dir = 0 00_0001 = User execute fault - priv = 0 dir = 1 dtype = 1 00_0000 = No fault
0x102C fault_attr_status ro — Fault Attribute Status register
  [31:20] ? — XID.
  [19:8] ? — Route ID.
  [7:0] ? — Privilege ID.
0x1030 fault_clear wo
  [0] ? — Fault clear. Writing a 1 clears the current fault. Writing a 0 has no effect.
